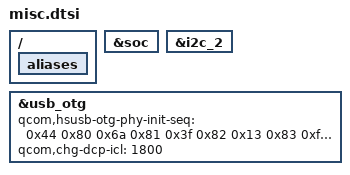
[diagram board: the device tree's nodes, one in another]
/ {
	aliases {
		/delete-property/ i2c4;
	};
};

&soc {
	/delete-node/ i2c@78b8000;

};

&i2c_2 {
	/delete-node/ adv7533@39;
	/delete-node/ pericom-type-c@1d;
};

&usb_otg {
	qcom,hsusb-otg-phy-init-seq =
		<0x44 0x80 0x6a 0x81 0x3f 0x82 0x13 0x83 0xffffffff>;
	qcom,chg-dcp-icl = <1800>;
};
